# ATSAM4SD16B device description
Architecture: CORTEX-M4; Family: SAM4; Series: SAM4S
Registers are 32-bit, read-write, no defined reset value unless marked. A register's access mark holds for its fields unless they carry their own. Offsets are from the block's base; [hi:lo] are bit positions; {n}, {i} and the like mark numbered series.

## CMCC — Cortex-M Cache Controller
Instances: CMCC 0x4007C000
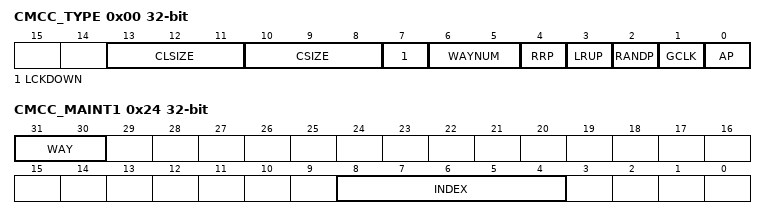
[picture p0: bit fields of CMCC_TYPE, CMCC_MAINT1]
0x00 CMCC_TYPE ro — Cache Controller Type Register
  [13:11] CLSIZE — Cache LIne Size
    0=CLSIZE_1KB (Cache line size is 4 bytes); 1=CLSIZE_2KB (Cache line size is 8 bytes); 2=CLSIZE_4KB (Cache line size is 16 bytes); 3=CLSIZE_8KB (Cache line size is 32 bytes)
  [10:8] CSIZE — Data Cache Size
    0=CSIZE_1KB (Data cache size is 1 Kbyte); 1=CSIZE_2KB (Data cache size is 2 Kbytes); 2=CSIZE_4KB (Data cache size is 4 Kbytes); 3=CSIZE_8KB (Data cache size is 8 Kbytes)
  [7] LCKDOWN — Lockdown Supported
  [6:5] WAYNUM — Number of Ways
    0=DMAPPED (Direct Mapped Cache); 1=ARCH2WAY (2-way set associative); 2=ARCH4WAY (4-way set associative); 3=ARCH8WAY (8-way set associative)
  [4] RRP — Random Selection Policy Supported
  [3] LRUP — Least Recently Used Policy Supported
  [2] RANDP — Random Selection Policy Supported
  [1] GCLK — Dynamic Clock Gating Supported
  [0] AP — Access Port Access Allowed
0x04 CMCC_CFG — Cache Controller Configuration Register
  [0] GCLKDIS — Disable Clock Gating
0x08 CMCC_CTRL wo — Cache Controller Control Register
  [0] CEN — Cache Controller Enable
0x0C CMCC_SR ro — Cache Controller Status Register
  [0] CSTS — Cache Controller Status
0x20 CMCC_MAINT0 wo — Cache Controller Maintenance Register 0
  [0] INVALL — Cache Controller Invalidate All
0x24 CMCC_MAINT1 wo — Cache Controller Maintenance Register 1
  [31:30] WAY — Invalidate Way
    {v}=Way {v} is selection for index invalidation (v=0..3)
  [8:4] INDEX — Invalidate Index
0x28 CMCC_MCFG — Cache Controller Monitor Configuration Register
  [1:0] MODE — Cache Controller Monitor Counter Mode
    0=CYCLE_COUNT (Cycle counter); 1=IHIT_COUNT (Instruction hit counter); 2=DHIT_COUNT (Data hit counter)
0x2C CMCC_MEN — Cache Controller Monitor Enable Register
  [0] MENABLE — Cache Controller Monitor Enable
0x30 CMCC_MCTRL wo — Cache Controller Monitor Control Register
  [0] SWRST — Monitor
0x34 CMCC_MSR ro — Cache Controller Monitor Status Register
  [31:0] EVENT_CNT — Monitor Event Counter

## CRCCU — Cyclic Redundancy Check Calculation Unit
Instances: CRCCU 0x40044000
0x00 CRCCU_DSCR — CRCCU Descriptor Base Register
  [31:9] DSCR — Descriptor Base Address
0x08 CRCCU_DMA_EN wo — CRCCU DMA Enable Register
  [0] DMAEN — DMA Enable
0x0C CRCCU_DMA_DIS wo — CRCCU DMA Disable Register
  [0] DMADIS — DMA Disable
0x10 CRCCU_DMA_SR ro — CRCCU DMA Status Register
  [0] DMASR — DMA Status
0x14 CRCCU_DMA_IER wo — CRCCU DMA Interrupt Enable Register
  [0] DMAIER — Interrupt Enable
0x18 CRCCU_DMA_IDR wo — CRCCU DMA Interrupt Disable Register
  [0] DMAIDR — Interrupt Disable
0x1C CRCCU_DMA_IMR ro — CRCCU DMA Interrupt Mask Register
  [0] DMAIMR — Interrupt Mask
0x20 CRCCU_DMA_ISR ro — CRCCU DMA Interrupt Status Register
  [0] DMAISR — Interrupt Status
0x34 CRCCU_CR wo — CRCCU Control Register
  [0] RESET — CRC Computation Reset
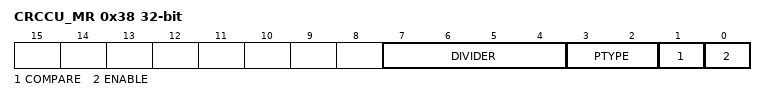
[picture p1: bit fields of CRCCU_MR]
0x38 CRCCU_MR — CRCCU Mode Register
  [7:4] DIVIDER — Request Divider
  [3:2] PTYPE — Primitive Polynomial
    0=CCITT8023 (Polynom 0x04C11DB7); 1=CASTAGNOLI (Polynom 0x1EDC6F41); 2=CCITT16 (Polynom 0x1021)
  [1] COMPARE — CRC Compare
  [0] ENABLE — CRC Enable
0x3C CRCCU_SR ro — CRCCU Status Register
  [31:0] CRC — Cyclic Redundancy Check Value
0x40 CRCCU_IER wo — CRCCU Interrupt Enable Register
  [0] ERRIER — CRC Error Interrupt Enable
0x44 CRCCU_IDR wo — CRCCU Interrupt Disable Register
  [0] ERRIDR — CRC Error Interrupt Disable
0x48 CRCCU_IMR ro — CRCCU Interrupt Mask Register
  [0] ERRIMR — CRC Error Interrupt Mask
0x4C CRCCU_ISR ro — CRCCU Interrupt Status Register
  [0] ERRISR — CRC Error Interrupt Status

## EFC — Embedded Flash Controller
Instances: EFC0 0x400E0A00, EFC1 0x400E0C00
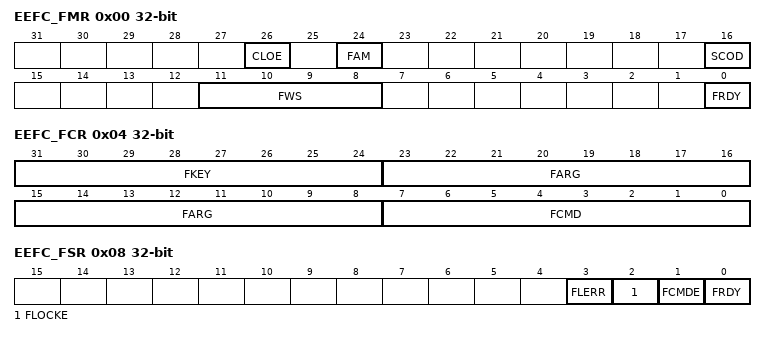
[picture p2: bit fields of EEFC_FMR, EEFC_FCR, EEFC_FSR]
0x00 EEFC_FMR — EEFC Flash Mode Register
  [26] CLOE — Code Loop Optimization Enable
  [24] FAM — Flash Access Mode
  [16] SCOD — Sequential Code Optimization Disable
  [11:8] FWS — Flash Wait State
  [0] FRDY — Flash Ready Interrupt Enable
0x04 EEFC_FCR wo — EEFC Flash Command Register
  [31:24] FKEY — Flash Writing Protection Key
    90=PASSWD (The 0x5A value enables the command defined by the bits of the register. If the field is written with a different value, the write is not performed and no action is started.)
  [23:8] FARG — Flash Command Argument
  [7:0] FCMD — Flash Command
    0=GETD (Get Flash descriptor); 1=WP (Write page); 2=WPL (Write page and lock); 3=EWP (Erase page and write page); 4=EWPL (Erase page and write page then lock); 5=EA (Erase all); 7=EPA (Erase pages); 8=SLB (Set lock bit); 9=CLB (Clear lock bit); 10=GLB (Get lock bit); 11=SGPB (Set GPNVM bit); 12=CGPB (Clear GPNVM bit); 13=GGPB (Get GPNVM bit); 14=STUI (Start read unique identifier); 15=SPUI (Stop read unique identifier); 16=GCALB (Get CALIB bit); 17=ES (Erase sector); 18=WUS (Write user signature); 19=EUS (Erase user signature); 20=STUS (Start read user signature); 21=SPUS (Stop read user signature)
0x08 EEFC_FSR ro — EEFC Flash Status Register
  [3] FLERR — Flash Error Status (cleared when a programming operation starts)
  [2] FLOCKE — Flash Lock Error Status (cleared on read)
  [1] FCMDE — Flash Command Error Status (cleared on read or by writing EEFC_FCR)
  [0] FRDY — Flash Ready Status (cleared when Flash is busy)
0x0C EEFC_FRR ro — EEFC Flash Result Register
  [31:0] FVALUE — Flash Result Value

## Notices in the file
SAM Software Package License
Copyright (c) %copyright_year%, Atmel Corporation
All rights reserved.
Redistribution and use in source and binary forms, with or without
modification, are permitted provided that the following condition is met:
- Redistributions of source code must retain the above copyright notice,
this list of conditions and the disclaimer below.
Atmel's name may not be used to endorse or promote products derived from
this software without specific prior written permission.
DISCLAIMER:  THIS SOFTWARE IS PROVIDED BY ATMEL "AS IS" AND ANY EXPRESS OR
IMPLIED WARRANTIES, INCLUDING, BUT NOT LIMITED TO, THE IMPLIED WARRANTIES OF
MERCHANTABILITY, FITNESS FOR A PARTICULAR PURPOSE AND NON-INFRINGEMENT ARE
DISCLAIMED. IN NO EVENT SHALL ATMEL BE LIABLE FOR ANY DIRECT, INDIRECT,
INCIDENTAL, SPECIAL, EXEMPLARY, OR CONSEQUENTIAL DAMAGES (INCLUDING, BUT NOT
LIMITED TO, PROCUREMENT OF SUBSTITUTE GOODS OR SERVICES; LOSS OF USE, DATA,
OR PROFITS; OR BUSINESS INTERRUPTION) HOWEVER CAUSED AND ON ANY THEORY OF
LIABILITY, WHETHER IN CONTRACT, STRICT LIABILITY, OR TORT (INCLUDING
NEGLIGENCE OR OTHERWISE) ARISING IN ANY WAY OUT OF THE USE OF THIS SOFTWARE,
EVEN IF ADVISED OF THE POSSIBILITY OF SUCH DAMAGE.
